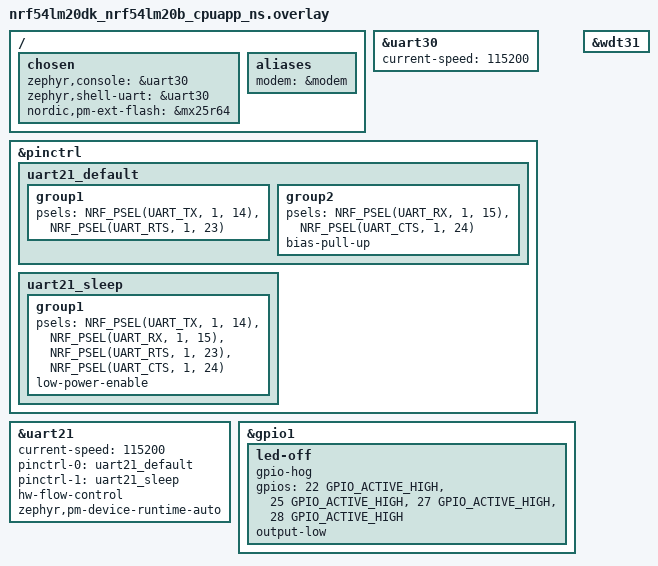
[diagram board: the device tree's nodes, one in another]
/*
 * Copyright (c) 2026 Nordic Semiconductor ASA
 *
 * SPDX-License-Identifier: LicenseRef-Nordic-5-Clause
 *
 * nRF54LM20B DK + nRF9151 DK.
 *
 * Default build (no shield):
 *   west build -b nrf54lm20dk/nrf54lm20b/cpuapp/ns -p
 *
 * Console uses uart30 (VCOM0) so plain and nRF7002-EB2 builds share the same
 * USB serial port.
 *
 * The Serial Modem link uses uart21 on P1.14–P1.15 (TX/RX, P2 connector) and
 * P1.23–P1.24 (RTS/CTS, P3 connector). DTR/RI/reset use P1.11/P1.12/P1.10
 * (P2 connector).
 *
 * Application button 1 is BUTTON0 and button 2 is BUTTON1. BUTTON3 is removed,
 * as it is the only button on gpio0. The DK library adds one GPIO callback to
 * every port that has a button, and linking it into both port lists drops the
 * other gpio1 callbacks (nRF70 host IRQ, Serial Modem RI).
 *
 * With nRF7002-EB2 on the P17 expansion header (Wi-Fi location), pass
 * -DSHIELD=nrf7002eb2. The shield does not conflict with uart20 (VCOM1).
 *
 * Set matching VDD on both DKs (typically 1.8 V).
 *
 * Wiring: see docs/getting-started/ppp-nrf54.md.
 *
 * RRAM/SRAM partitions: nrf54lm20_cpuapp_ns_partitions.dtsi (MCUboot + TF-M).
 */

#include "nrf54lm20_cpuapp_ns_partitions.dtsi"

/ {
	chosen {
		zephyr,console = &uart30;
		zephyr,shell-uart = &uart30;
		nordic,pm-ext-flash = &mx25r64;
	};

	aliases {
		modem = &modem;
		/delete-property/ sw3;
	};
};

/delete-node/ &button3;

&uart30 {
	status = "okay";
	current-speed = <115200>;
};

&pinctrl {
	uart21_default: uart21_default {
		group1 {
			psels = <NRF_PSEL(UART_TX, 1, 14)>,
				<NRF_PSEL(UART_RTS, 1, 23)>;
		};

		group2 {
			psels = <NRF_PSEL(UART_RX, 1, 15)>,
				<NRF_PSEL(UART_CTS, 1, 24)>;
			bias-pull-up;
		};
	};

	uart21_sleep: uart21_sleep {
		group1 {
			psels = <NRF_PSEL(UART_TX, 1, 14)>,
				<NRF_PSEL(UART_RX, 1, 15)>,
				<NRF_PSEL(UART_RTS, 1, 23)>,
				<NRF_PSEL(UART_CTS, 1, 24)>;
			low-power-enable;
		};
	};
};

&uart21 {
	status = "okay";
	current-speed = <115200>;
	pinctrl-0 = <&uart21_default>;
	pinctrl-1 = <&uart21_sleep>;
	pinctrl-names = "default", "sleep";
	hw-flow-control;
	zephyr,pm-device-runtime-auto;

	#include "nrf54lm20_modem.dtsi"
};

&gpio1 {
	status = "okay";

	/* The LEDs are unused. Drive them low instead of leaving the pins floating. */
	led-off {
		gpio-hog;
		gpios = <22 GPIO_ACTIVE_HIGH>, <25 GPIO_ACTIVE_HIGH>,
			<27 GPIO_ACTIVE_HIGH>, <28 GPIO_ACTIVE_HIGH>;
		output-low;
	};
};

/* Non-secure hardware watchdog, fallback for CONFIG_TASK_WDT_HW_FALLBACK. */
&wdt31 {
	status = "okay";
};
